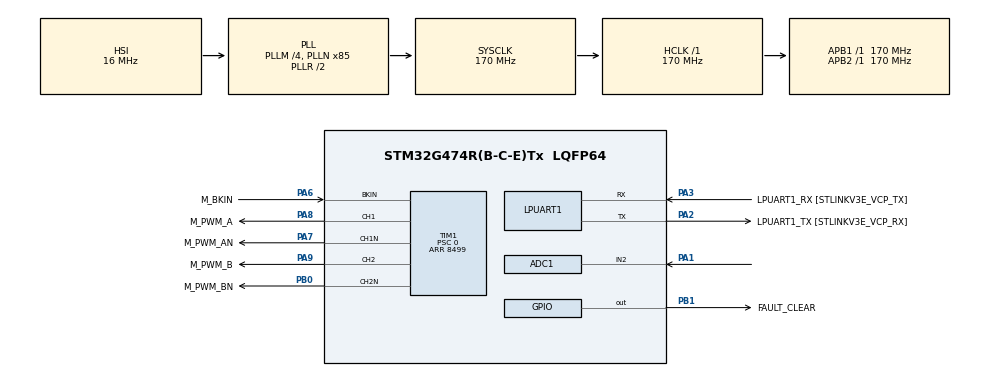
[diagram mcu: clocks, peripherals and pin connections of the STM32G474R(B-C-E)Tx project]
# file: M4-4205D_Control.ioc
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ADC1.Channel-1\#ChannelRegularConversion=ADC_CHANNEL_2
ADC1.ExternalTrigConv=ADC_EXTERNALTRIG_T6_TRGO
ADC1.ExternalTrigConvEdge=ADC_EXTERNALTRIGCONVEDGE_RISING
ADC1.NbrOfConversionFlag=1
ADC1.OffsetNumber-1\#ChannelRegularConversion=ADC_OFFSET_NONE
ADC1.Overrun=ADC_OVR_DATA_OVERWRITTEN
ADC1.Rank-1\#ChannelRegularConversion=1
ADC1.SamplingTime-1\#ChannelRegularConversion=ADC_SAMPLETIME_92CYCLES_5
ADC1.master=1
Mcu.Family=STM32G4
Mcu.Name=STM32G474R(B-C-E)Tx
Mcu.Package=LQFP64
NVIC.ADC1_2_IRQn=true\:1\:0\:false\:false\:true\:false\:true\:false
NVIC.LPUART1_IRQn=true\:3\:0\:false\:false\:true\:false\:true\:false
NVIC.PriorityGroup=NVIC_PRIORITYGROUP_4
PA1.Mode=IN2-Single-Ended
PA1.Signal=ADC1_IN2
PA13.GPIO_Label=T_SWDIO
PA13.Mode=Trace_Asynchronous_SW
PA13.Signal=SYS_JTMS-SWDIO
PA14.GPIO_Label=T_SWCLK
PA14.Mode=Trace_Asynchronous_SW
PA14.Signal=SYS_JTCK-SWCLK
PA2.GPIO_Label=LPUART1_TX [STLINKV3E_VCP_RX]
PA2.Mode=Asynchronous
PA2.Signal=LPUART1_TX
PA3.GPIO_Label=LPUART1_RX [STLINKV3E_VCP_TX]
PA3.Mode=Asynchronous
PA3.Signal=LPUART1_RX
PA6.GPIO_Label=M_BKIN
PA6.Mode=Activate-Break-Input
PA6.Signal=TIM1_BKIN
PA7.GPIO_Label=M_PWM_AN
PA7.Mode=PWM Generation1 CH1 CH1N
PA7.Signal=TIM1_CH1N
PA8.GPIO_Label=M_PWM_A
PA8.Signal=S_TIM1_CH1
PA9.GPIO_Label=M_PWM_B
PA9.Signal=S_TIM1_CH2
PB0.GPIO_Label=M_PWM_BN
PB0.Mode=PWM Generation2 CH2 CH2N
PB0.Signal=TIM1_CH2N
PB1.GPIO_Label=FAULT_CLEAR
PB1.GPIO_PuPd=GPIO_NOPULL
PB1.Signal=GPIO_Output
PB3.GPIO_Label=T_SWO
PB3.Mode=Trace_Asynchronous_SW
PB3.Signal=SYS_JTDO-SWO
PC14-OSC32_IN.GPIO_Label=RCC_OSC32_IN
PC14-OSC32_IN.Mode=LSE-External-Oscillator
PC14-OSC32_IN.Signal=RCC_OSC32_IN
PC15-OSC32_OUT.GPIO_Label=RCC_OSC32_OUT
PC15-OSC32_OUT.Mode=LSE-External-Oscillator
PC15-OSC32_OUT.Signal=RCC_OSC32_OUT
PF0-OSC_IN.GPIO_Label=RCC_OSC_IN
PF0-OSC_IN.Mode=HSE-External-Oscillator
PF0-OSC_IN.Signal=RCC_OSC_IN
PF1-OSC_OUT.GPIO_Label=RCC_OSC_OUT
PF1-OSC_OUT.Mode=HSE-External-Oscillator
PF1-OSC_OUT.Signal=RCC_OSC_OUT
ProjectManager.HeapSize=0x200
ProjectManager.StackSize=0x400
ProjectManager.TargetToolchain=STM32CubeIDE
RCC.ADC12Freq_Value=170000000
RCC.ADC345Freq_Value=170000000
RCC.AHBFreq_Value=170000000
RCC.APB1Freq_Value=170000000
RCC.APB1TimFreq_Value=170000000
RCC.APB2Freq_Value=170000000
RCC.APB2TimFreq_Value=170000000
RCC.CortexFreq_Value=170000000
RCC.EXTERNAL_CLOCK_VALUE=12288000
RCC.HCLKFreq_Value=170000000
RCC.HSE_VALUE=24000000
RCC.HSI48_VALUE=48000000
RCC.HSI_VALUE=16000000
RCC.PLLM=RCC_PLLM_DIV4
RCC.PLLN=85
RCC.RTCClockSelection=RCC_RTCCLKSOURCE_LSE
RCC.SYSCLKFreq_VALUE=170000000
RCC.SYSCLKSource=RCC_SYSCLKSOURCE_PLLCLK
RCC.USBFreq_Value=170000000
RCC.VCOOutputFreq_Value=340000000
SH.S_TIM1_CH1.0=TIM1_CH1,PWM Generation1 CH1 CH1N
SH.S_TIM1_CH2.0=TIM1_CH2,PWM Generation2 CH2 CH2N
TIM1.AutomaticOutput=TIM_AUTOMATICOUTPUT_DISABLE
TIM1.BreakPolarity=TIM_BREAKPOLARITY_LOW
TIM1.BreakState=TIM_BREAK_ENABLE
TIM1.Channel-PWM\ Generation1\ CH1\ CH1N=TIM_CHANNEL_1
TIM1.Channel-PWM\ Generation2\ CH2\ CH2N=TIM_CHANNEL_2
TIM1.DeadTime=149
TIM1.PeriodNoDither=8499
TIM1.Prescaler=0
TIM6.Period=999
TIM6.Prescaler=169
TIM6.TIM_MasterOutputTrigger=TIM_TRGO_UPDATE
VP_SYS_VS_DBSignals.Mode=DisableDeadBatterySignals
VP_TIM6_VS_ClockSourceINT.Mode=Enable_Timer
board=NUCLEO-G474RE

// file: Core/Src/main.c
/* USER CODE BEGIN Header */
/**
  ******************************************************************************
  * @file           : main.c
  * @brief          : Main program body
  ******************************************************************************
  * @attention
  *
  * Copyright (c) 2026 STMicroelectronics.
  * All rights reserved.
  *
  * This software is licensed under terms that can be found in the LICENSE file
  * in the root directory of this software component.
  * If no LICENSE file comes with this software, it is provided AS-IS.
  *
  ******************************************************************************
  */
/* USER CODE END Header */
#include "main.h"
#include "adc.h"
#include "usart.h"
#include "tim.h"
#include "gpio.h"

/* USER CODE BEGIN Includes */
#include "speed_control.h"
#include "tach_sensor.h"
#include "motor_cli.h"
/* USER CODE END Includes */

void SystemClock_Config(void);

int main(void)
{

  /* MCU Configuration--------------------------------------------------------*/

  /* Reset of all peripherals, Initializes the Flash interface and the Systick. */
  HAL_Init();

  /* Configure the system clock */
  SystemClock_Config();

  /* Initialize all configured peripherals */
  MX_GPIO_Init();
  MX_LPUART1_UART_Init();
  MX_TIM6_Init();
  MX_ADC1_Init();
  MX_TIM1_Init();
  /* USER CODE BEGIN 2 */
  SpeedControl_Init();
  /* Arm the ADC before TIM6, so the very first TRGO already has somewhere to
   * go. TIM6 runs without its own interrupt now -- it only paces TRGO, and
   * the control loop runs from ADC end-of-conversion. */
  TachSensor_Init();
  MotorCli_Init();
  HAL_TIM_Base_Start(&htim6);
  /* USER CODE END 2 */

  /* Infinite loop */
  while (1)
  {

    /* USER CODE BEGIN 3 */

    /* Background work only. The control loop runs from the ADC ISR and
     * preempts everything here, so nothing in this loop can delay it. */
    MotorCli_Task();				/* CLI RX/TX, command parsing, and telemetry streaming */
    SpeedControl_WatchdogTask();	/* Watchdog for the control loop, which runs from ADC ISR */
  }
  /* USER CODE END 3 */
}

void SystemClock_Config(void)
{
  RCC_OscInitTypeDef RCC_OscInitStruct = {0};
  RCC_ClkInitTypeDef RCC_ClkInitStruct = {0};

  /** Configure the main internal regulator output voltage
  */
  HAL_PWREx_ControlVoltageScaling(PWR_REGULATOR_VOLTAGE_SCALE1_BOOST);

  /** Initializes the RCC Oscillators according to the specified parameters
  * in the RCC_OscInitTypeDef structure.
  */
  RCC_OscInitStruct.OscillatorType = RCC_OSCILLATORTYPE_HSI;
  RCC_OscInitStruct.HSIState = RCC_HSI_ON;
  RCC_OscInitStruct.HSICalibrationValue = RCC_HSICALIBRATION_DEFAULT;
  RCC_OscInitStruct.PLL.PLLState = RCC_PLL_ON;
  RCC_OscInitStruct.PLL.PLLSource = RCC_PLLSOURCE_HSI;
  RCC_OscInitStruct.PLL.PLLM = RCC_PLLM_DIV4;
  RCC_OscInitStruct.PLL.PLLN = 85;
  RCC_OscInitStruct.PLL.PLLP = RCC_PLLP_DIV2;
  RCC_OscInitStruct.PLL.PLLQ = RCC_PLLQ_DIV2;
  RCC_OscInitStruct.PLL.PLLR = RCC_PLLR_DIV2;
  if (HAL_RCC_OscConfig(&RCC_OscInitStruct) != HAL_OK)
  {
    Error_Handler();
  }

  /** Initializes the CPU, AHB and APB buses clocks
  */
  RCC_ClkInitStruct.ClockType = RCC_CLOCKTYPE_HCLK|RCC_CLOCKTYPE_SYSCLK
                              |RCC_CLOCKTYPE_PCLK1|RCC_CLOCKTYPE_PCLK2;
  RCC_ClkInitStruct.SYSCLKSource = RCC_SYSCLKSOURCE_PLLCLK;
  RCC_ClkInitStruct.AHBCLKDivider = RCC_SYSCLK_DIV1;
  RCC_ClkInitStruct.APB1CLKDivider = RCC_HCLK_DIV1;
  RCC_ClkInitStruct.APB2CLKDivider = RCC_HCLK_DIV1;

  if (HAL_RCC_ClockConfig(&RCC_ClkInitStruct, FLASH_LATENCY_4) != HAL_OK)
  {
    Error_Handler();
  }
}

void Error_Handler(void)
{
  __disable_irq();
  while (1)
  {
  }
}
